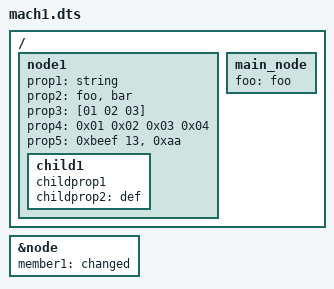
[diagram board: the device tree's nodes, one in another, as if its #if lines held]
/dts-v1/;

#include "common.dtsi"

/ {
    node1 {
        prop1 = "string";
        prop2 = "foo", "bar";
        prop3 = [01 02 03];
        prop4 = <0x01 0x02 0x03 0x04>;
        prop5 = <0xbeef 13>, "foobar", [ab cd], <0xaa>;

        child1 {
            childprop1;
            childprop2 = "def";
        };
    };
};

#ifdef MAIN
/ {
    main_node {
        foo = "foo";
    };
};
#endif

&node {
    member1 = "changed";
};
